# STM32C542 register map
File version: 0.1
CPU: CM33 r0p4, little endian, MPU, FPU, 4 interrupt priority bits
Registers are 32-bit, read-write, reset 0x0 unless marked. A register's access mark holds for its fields unless they carry their own. Offsets are from the block's base; lines under a group give offsets from that group; [hi:lo] are bit positions; {n}, {i} and the like mark numbered series; 'fields as' and 'values as' point back to an identical list; <NAME> marks a mode.

## Memory map
0x40003400 OPAMP1 size 0x400 — OPAMP register block
0x40022000 FLASH size 0x400 — FLASH register block
0x40026000 RAMCFG size 0x400 — RAMCFG register block
0x40030400 ICACHE size 0x400 — ICACHE register block
0x42020000 GPIOA size 0x2C — GPIO address block description
0x42020400 GPIOB size 0x2C — GPIO address block description
0x42020800 GPIOC size 0x2C — GPIO address block description
0x42020C00 GPIOD size 0x2C
0x42021000 GPIOE size 0x2C
0x42021C00 GPIOH size 0x2C
0x42028400 DAC1 size 0x400 — DAC register block
0x420C0000 AES size 0x400 — AES register block
0x44020800 PWR size 0x400 — PWR register block
0x44020C00 RCC size 0x400 — RCC register block
0x44022000 EXTI size 0x400 — EXTI register block
0x44024000 DBGMCU size 0x1000 — DBGMCU address block description

## Interrupts
1 PWR_PVD (PWR) — Power Voltage Monitor
4 RAMCFG — RAM configuration global interrupt
5 FLASH — Flash non-secure global interrupt
6 RCC — RCC non-secure global interrupt
{n+7} EXTI{n} (EXTI) (n=0..15) — EXTI Line{n} interrupt
66 ICACHE — Instruction cache global interrupt
68 AES — AES global interrupt
77 DAC1 — DAC global interrupt

## AES — AES register block
Base 0x420C0000
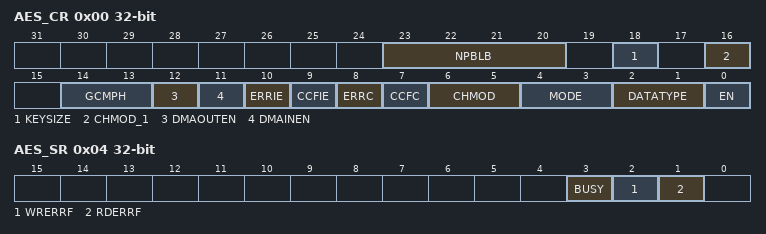
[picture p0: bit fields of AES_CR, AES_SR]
0x00 AES_CR — AES control register
  [23:20] NPBLB — Number of padding bytes in last block
    0=All bytes are valid (no padding); 1=Padding for the last LSB byte; 15=Padding for the 15 LSB bytes of last block
  [18] KEYSIZE — Key size selection
    0=128-bit; 1=256-bit
  [16] CHMOD_1 — CHMOD[2]
  [14:13] GCMPH — GCM or CCM phase selection
    0=Initialization phase; 1=Header phase; 2=Payload phase; 3=Final phase
  [12] DMAOUTEN — DMA output enable
    0=Disable; 1=Enable
  [11] DMAINEN — DMA input enable
    0=Disable; 1=Enable
  [10] ERRIE — Error interrupt enable
    0=Disabled (masked); 1=Enabled (not masked)
  [9] CCFIE — Computation complete flag interrupt enable
    0=Disabled (masked); 1=Enabled (not masked)
  [8] ERRC — Error flag clear
  [7] CCFC — Computation complete flag clear
  [6:5] CHMOD — CHMOD[1:0]: Chaining mode
    0=Electronic codebook (ECB); 1=Cipher-block chaining (CBC); 2=Counter mode (CTR); 3=Galois counter mode (GCM) and Galois message authentication code (GMAC)
  [4:3] MODE — Operating mode
    0=Encryption; 1=Key derivation (or key preparation), for ECB/CBC decryption only; 2=Decryption
  [2:1] DATATYPE
    0=No swapping (32-bit data); 1=Half-word swapping (16-bit data); 2=Byte swapping (8-bit data); 3=Bit-level swapping
  [0] EN — Enable
    0=Disable; 1=Enable
0x04 AES_SR ro — AES status register
  [3] BUSY
    0=Idle; 1=Busy
  [2] WRERRF — Write error flag
    0=No error; 1=Unexpected write to AES_DINR register occurred during computation or data output phase
  [1] RDERRF — Read error flag
    0=No error; 1=Unexpected read to AES_DOUTR register occurred during computation or data input phase
0x08 AES_DINR wo — AES data input register
  [31:0] DIN — Data input
0x0C AES_DOUTR ro — AES data output register
  [31:0] DOUT — Data output
{0x10+4i} AES_KEYR{i} wo (i=0..3) — AES key register {i}
  [31:0] KEY — Cryptographic key, bits [{32i+31}:{32i}]
{0x20+4i} AES_IVR{i} (i=0..3) — AES initialization vector register {i}
  [31:0] IVI — Initialization vector input, bits [{32i+31}:{32i}]
{0x20+4i} AES_KEYR{i} wo (i=4..7) — AES key register {i}
  [31:0] KEY — Cryptographic key, bits [{32i+31}:{32i}]
{0x40+4i} AES_SUSPR{i} (i=0..7) — AES suspend registers
  [31:0] SUSP — Suspend data

## ICACHE — ICACHE register block
Base 0x40030400
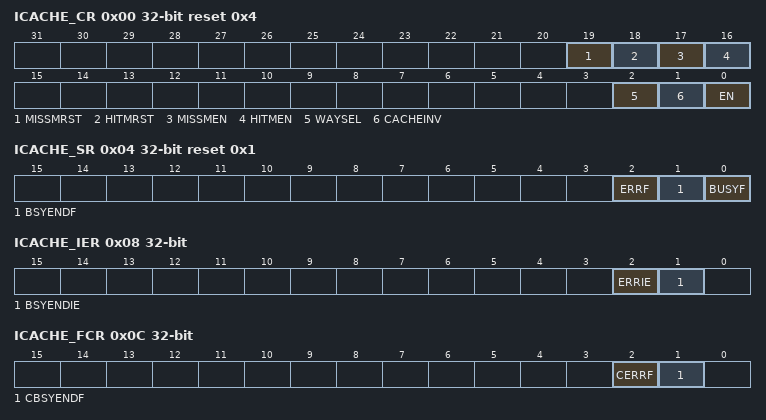
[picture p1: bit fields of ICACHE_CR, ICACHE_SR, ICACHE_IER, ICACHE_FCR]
0x00 ICACHE_CR reset 0x4 — ICACHE control register
  [19] MISSMRST — miss monitor reset
    0=release the cache miss monitor reset (needed to enable the counting); 1=reset cache miss monitor
  [18] HITMRST — hit monitor reset
    0=release the cache miss monitor reset (needed to enable the counting); 1=reset cache hit monitor
  [17] MISSMEN — miss monitor enable
    0=cache miss monitor switched off. Stopping the monitor does not reset it.; 1=cache miss monitor enabled
  [16] HITMEN — hit monitor enable
    0=cache hit monitor switched off. Stopping the monitor does not reset it.; 1=cache hit monitor enabled
  [2] WAYSEL — cache associativity mode selection
    0=direct mapped cache (1-way cache); 1=n-way set associative cache (reset value)
  [1] CACHEINV wo — cache invalidation
    0=no effect; 1=invalidate entire cache (all cache lines valid bit = 0)
  [0] EN — enable
    0=cache disabled; 1=cache enabled
0x04 ICACHE_SR ro reset 0x1 — ICACHE status register
  [2] ERRF — cache error flag
    0=no error; 1=an error occurred during the operation (cacheable write)
  [1] BSYENDF — busy end flag
    0=cache busy; 1=full invalidate CACHEINV operation finished
  [0] BUSYF — busy flag
    0=cache not busy on a CACHEINV operation; 1=cache executing a full invalidate CACHEINV operation
0x08 ICACHE_IER — ICACHE interrupt enable register
  [2] ERRIE — interrupt enable on cache error
    0=interrupt disabled on error; 1=interrupt enabled on error
  [1] BSYENDIE — interrupt enable on busy end
    0=interrupt disabled on busy end; 1=interrupt enabled on busy end
0x0C ICACHE_FCR wo — ICACHE flag clear register
  [2] CERRF — clear cache error flag
    0=no effect; 1=clears ERRF flag in ICACHE_SR
  [1] CBSYENDF — clear busy end flag
    0=no effect; 1=clears BSYENDF flag in ICACHE_SR
0x10 ICACHE_HMONR ro — ICACHE hit monitor register
  [31:0] HITMON — cache hit monitor counter
0x14 ICACHE_MMONR ro — ICACHE miss monitor register
  [15:0] MISSMON — cache miss monitor counter
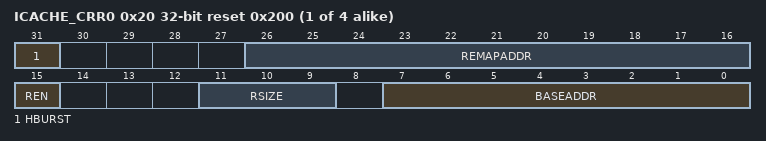
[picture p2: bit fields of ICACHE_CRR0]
{0x20+4i} ICACHE_CRR{i} reset 0x200 (i=0..3) — ICACHE region {i} configuration register
  [31] HBURST — output burst type for region x
    0=WRAP; 1=INCR
  [26:16] REMAPADDR — remapped address for region x
  [15] REN — enable for region x
    0=disabled; 1=enabled
  [11:9] RSIZE — size for region x
    1=2 Mbytes; 2=4 Mbytes; 3=8 Mbytes; 4=16 Mbytes; 5=32 Mbytes; 6=64 Mbytes; 7=128 Mbytes
  [7:0] BASEADDR — base address for region x

## Notices in the file
Copyright (c) 2025 STMicroelectronics.
SPDX-License-Identifier: Apache-2.0
Licensed under the Apache License, Version 2.0 (the "License");
you may not use this file except in compliance with the License.
You may obtain a copy of the License at
http://www.apache.org/licenses/LICENSE-2.0
Unless required by applicable law or agreed to in writing, software
distributed under the License is distributed on an "AS IS" BASIS,
WITHOUT WARRANTIES OR CONDITIONS OF ANY KIND, either express or implied.
See the License for the specific language governing permissions and
limitations under the License.
